# nrf5340_application register map
Vendor: Nordic Semiconductor; Series: nrf53; File version: 1
CPU: CM33 r0p4, little endian, MPU, FPU, 3 interrupt priority bits, 69 interrupts
Registers are 32-bit, read-write, reset 0x0 unless marked. A register's access mark holds for its fields unless they carry their own. Offsets are from the block's base; [hi:lo] are bit positions; lines under a group give offsets from that group; {n}, {i} and the like mark numbered series; 'fields as' and 'values as' point back to an identical list.

## CACHE_S — Cache
Base 0x50001000
{0x400+0x20*i} PROFILING[{i}] (i=0..1) group — Unspecified
  0x00 IHIT ro — Description cluster: Instruction fetch cache hit counter for cache region n, where n=0 means Flash and n=1 means XIP.
    [31:0] HITS — Number of instruction cache hits
  0x04 IMISS ro — Description cluster: Instruction fetch cache miss counter for cache region n, where n=0 means Flash and n=1 means XIP.
    [31:0] MISSES — Number of instruction cache misses
  0x08 DHIT ro — Description cluster: Data fetch cache hit counter for cache region n, where n=0 means Flash and n=1 means XIP.
    [31:0] HITS — Number of data cache hits
  0x0C DMISS ro — Description cluster: Data fetch cache miss counter for cache region n, where n=0 means Flash and n=1 means XIP.
    [31:0] MISSES — Number of data cache misses
0x500 ENABLE — Enable cache
  [0] ENABLE
    0=Disabled (Disable cache); 1=Enabled (Enable cache)
0x504 INVALIDATE wo — Invalidate the cache
  [0] INVALIDATE
    1=Invalidate the cache
0x508 ERASE wo — Erase the cache
  [0] ERASE
    1=Erase cache
0x50C PROFILINGENABLE — Enable the profiling counters
  [0] ENABLE
    0=Disable profiling; 1=Enable profiling
0x510 PROFILINGCLEAR wo — Clear the profiling counters
  [0] CLEAR — Clearing the profiling counters
    1=Clear the profiling counters
0x514 MODE — Cache mode. Switching from Cache to RAM mode causes the RAM to be cleared. Switching from RAM to Cache mode causes the cache to be invalidated.
  [0] MODE — Cache mode
    0=Cache mode; 1=Ram (RAM mode)
0x518 DEBUGLOCK rw-once — Lock debug mode Ignored in RAM mode.
  [0] DEBUGLOCK — Lock debug mode
    0=Unlocked (Debug mode unlocked); 1=Locked (Debug mode locked)
0x51C ERASESTATUS — Cache erase status
  [0] ERASESTATUS
    0=Idle (Erase is not complete or hasn't started); 1=Finished (Cache erase is finished)
0x520 WRITELOCK — Lock cache updates. Prevents updating of cache content on cache misses, but will continue to lookup instruction/data fetches in content already present in the cache. Ignored in RAM mode.
  [0] WRITELOCK — Lock cache updates
    0=Unlocked (Cache updates unlocked); 1=Locked (Cache updates locked)

## OSCILLATORS_NS — Oscillator control 0
Base 0x40004000
Same registers: OSCILLATORS_S 0x50004000
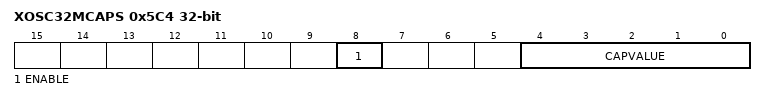
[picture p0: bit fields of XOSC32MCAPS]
0x5C4 XOSC32MCAPS — Programmable capacitance of XC1 and XC2
  [8] ENABLE — Enable on-chip capacitors on XC1 and XC2
    0=Disabled (Capacitor disabled (use external caps)); 1=Enabled (Capacitor enabled)
  [4:0] CAPVALUE — Value representing capacitance, calculated using provided equation
0x6C0 XOSC32KI group — Unspecified
  0x00 BYPASS — Enable or disable bypass of LFCLK crystal oscillator with external clock source
    [0] BYPASS
      0=Disabled (Disable (use with xtal or low-swing external source)); 1=Enabled (Enable (use with rail-to-rail external source))
  0x10 INTCAP — Control usage of internal load capacitors
    [1:0] INTCAP
      0=External (Use external load capacitors); 1=C6PF (6 pF internal load capacitance); 2=C7PF (7 pF internal load capacitance); 3=C11PF (11 pF internal load capacitance)

## REGULATORS_NS — Voltage regulators 0
Base 0x40004000; alternate view of OSCILLATORS_NS
Same registers: REGULATORS_S 0x50004000 (alternate view of OSCILLATORS_S)
0x428 MAINREGSTATUS ro — Main supply status
  [0] VREGH — VREGH status
    0=Inactive (Normal voltage mode. Voltage supplied on VDD and VDDH.); 1=Active (High voltage mode. Voltage supplied on VDDH.)
0x500 SYSTEMOFF wo
  [0] SYSTEMOFF — Enable System OFF mode
    1=Enter (Enable System OFF mode)
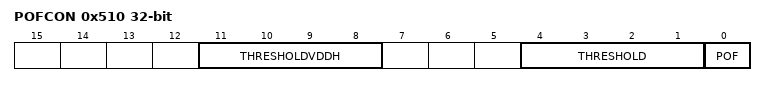
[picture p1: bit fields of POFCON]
0x510 POFCON — Power-fail comparator configuration
  [11:8] THRESHOLDVDDH — Power-fail comparator threshold setting for voltage supply on VDDH
    0=V27 (Set threshold to 2.7 V); 1=V28 (Set threshold to 2.8 V); 2=V29 (Set threshold to 2.9 V); 3=V30 (Set threshold to 3.0 V); 4=V31 (Set threshold to 3.1 V); 5=V32 (Set threshold to 3.2 V); 6=V33 (Set threshold to 3.3 V); 7=V34 (Set threshold to 3.4 V); 8=V35 (Set threshold to 3.5 V); 9=V36 (Set threshold to 3.6 V); 10=V37 (Set threshold to 3.7 V); 11=V38 (Set threshold to 3.8 V); 12=V39 (Set threshold to 3.9 V); 13=V40 (Set threshold to 4.0 V); 14=V41 (Set threshold to 4.1 V); 15=V42 (Set threshold to 4.2 V)
  [4:1] THRESHOLD — Power-fail comparator threshold setting
    6=V19 (Set threshold to 1.9 V); 7=V20 (Set threshold to 2.0 V); 8=V21 (Set threshold to 2.1 V); 9=V22 (Set threshold to 2.2 V); 10=V23 (Set threshold to 2.3 V); 11=V24 (Set threshold to 2.4 V); 12=V25 (Set threshold to 2.5 V); 13=V26 (Set threshold to 2.6 V); 14=V27 (Set threshold to 2.7 V); 15=V28 (Set threshold to 2.8 V)
  [0] POF — Enable or disable power-fail comparator
    0=Disabled; 1=Enabled
0x704 VREGMAIN group — Unspecified
  0x00 DCDCEN — DC/DC enable register for VREGMAIN
    [0] DCDCEN — Enable or disable DC/DC converter
      0=Disabled; 1=Enabled
0x900 VREGRADIO group — Unspecified
  0x04 DCDCEN — DC/DC enable register for VREGRADIO
    fields as VREGMAIN.DCDCEN
0xB00 VREGH group — Unspecified
  0x00 DCDCEN — DC/DC enable register for VREGH
    fields as VREGMAIN.DCDCEN
